# STM32H573xx register map
File version: 1.0
Registers are 32-bit, read-write, reset 0x0 unless marked. A register's access mark holds for its fields unless they carry their own. Offsets are from the block's base; [hi:lo] are bit positions; {n}, {i} and the like mark numbered series; 'fields as' and 'values as' point back to an identical list.

## ICACHE — Instruction Cache
Base 0x40030400
Same registers: ICACHE_S 0x50030400
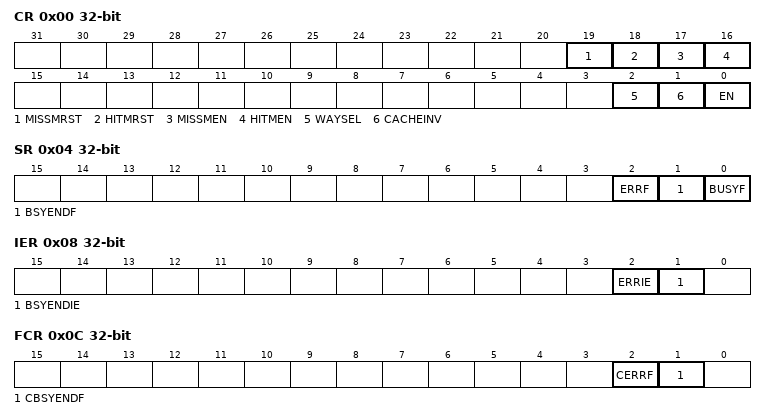
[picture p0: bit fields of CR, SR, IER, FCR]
0x00 CR — ICACHE control register
  [19] MISSMRST — Miss monitor reset
  [18] HITMRST — Hit monitor reset
  [17] MISSMEN — Miss monitor enable
  [16] HITMEN — Hit monitor enable
  [2] WAYSEL — Ways selection
    0=ICACHE_1WAY (1-way cache (direct mapped cache)); 1=ICACHE_2WAYS (2-ways set associative cache (default))
  [1] CACHEINV — Cache invalidation
  [0] EN — Enable
0x04 SR — ICACHE status register
  [2] ERRF — Cache error flag
  [1] BSYENDF — Busy end flag
  [0] BUSYF — Busy flag
0x08 IER — ICACHE interrupt enable register
  [2] ERRIE — Cache error interrupt enable
  [1] BSYENDIE — Busy end interrupt enable
0x0C FCR — ICACHE Flag clear register
  [2] CERRF — Cache error flag clear
  [1] CBSYENDF — Busy end flag clear
0x10 HMONR — ICACHE hit monitor register
  [31:0] HITMON — Cache hit monitor register
0x14 MMONR — ICACHE miss monitor register
  [15:0] MISSMON — Cache miss monitor register
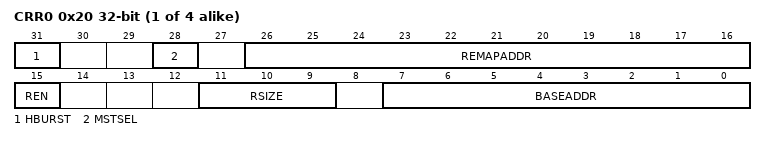
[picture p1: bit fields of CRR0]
{0x20+4i} CRR{i} (i=0..3) — ICACHE region {i} configuration register
  [31] HBURST — Region X output burst type
  [28] MSTSEL — Region X AHB cache master selection
  [26:16] REMAPADDR — Remap address of Region X to be remapped
  [15] REN — Region X enable
  [11:9] RSIZE — Region X size
  [7:0] BASEADDR — Base address of region X to remap

## DCACHE1 — Data Cache
Base 0x40031400
Same registers: DCACHE1_S 0x50031400
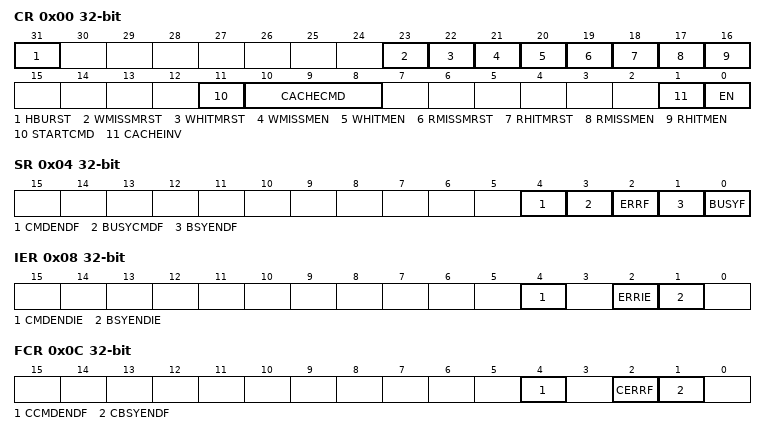
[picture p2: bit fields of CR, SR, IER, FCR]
0x00 CR — DCACHE control register
  [31] HBURST — Read burst type
    0=WRAP; 1=INCR
  [23] WMISSMRST — Write Miss monitor reset
  [22] WHITMRST — Write Hit monitor reset
  [21] WMISSMEN — Write Miss monitor enable
  [20] WHITMEN — Write Hit monitor enable
  [19] RMISSMRST — Read Miss monitor reset
  [18] RHITMRST — Read Hit monitor reset
  [17] RMISSMEN — Read Miss monitor enable
  [16] RHITMEN — Read Hit monitor enable
  [11] STARTCMD — Start command
  [10:8] CACHECMD — Cache command
    2=INVALIDATE_BY_ADDR; 1=CLEAN_BY_ADDR; 3=CLEAN_INVALIDATE_BY_ADDR; 0=NO_OPERATION
  [1] CACHEINV — Cache invalidation
  [0] EN — Enable
0x04 SR — DCACHE status register
  [4] CMDENDF — Command end flag
  [3] BUSYCMDF — Busy command flag
  [2] ERRF — Cache error flag
  [1] BSYENDF — Busy end flag
  [0] BUSYF — Busy flag
0x08 IER — DCACHE interrupt enable register
  [4] CMDENDIE — Command end interrupt enable
  [2] ERRIE — Cache error interrupt enable
  [1] BSYENDIE — Busy end interrupt enable
0x0C FCR — DCACHE Flag clear register
  [4] CCMDENDF — Command end flag clear
  [2] CERRF — Cache error flag clear
  [1] CBSYENDF — Busy end flag clear
0x10 RHMONR — DCACHE Read hit monitor register
  [31:0] RHITMON — Cache Read hit monitor register
0x14 RMMONR — DCACHE Read miss monitor register
  [15:0] RMISSMON — Cache Read miss monitor register
0x20 WHMONR — DCACHE Write hit monitor register
  [31:0] WHITMON — Cache Read hit monitor register
0x24 WMMONR — DCACHE Write miss monitor register
  [15:0] WMISSMON — Cache Read miss monitor register
0x28 CMDRSADDRR — DCACHE Command Start Address register
  [31:4] CMDSTARTADDR — Command start address
0x2C CMDREADDRR — DCACHE Command End Address register
  [31:4] CMDENDADDR — Command end address

## GTZC_TZSC1 — Global TrustZone Controller
Base 0x40032400
Same registers: GTZC_TZSC1_S 0x50032400
0x00 CR — TZSC control register
  [0] LCK
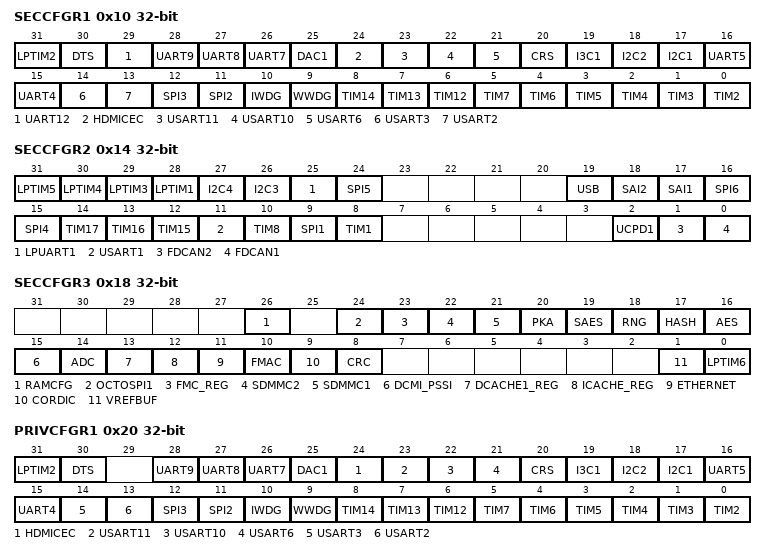
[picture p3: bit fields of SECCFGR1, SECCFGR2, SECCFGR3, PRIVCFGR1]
0x10 SECCFGR1 — TZSC secure configuration register 1
  [31] LPTIM2, [30] DTS, [29] UART12, [28] UART9, [27] UART8, [26] UART7, [25] DAC1, [24] HDMICEC, [23] USART11, [22] USART10, [21] USART6, [20] CRS, [19] I3C1, [18] I2C2, [17] I2C1, [16] UART5, [15] UART4, [14] USART3, [13] USART2, [12] SPI3, [11] SPI2, [10] IWDG, [9] WWDG, [8] TIM14, [7] TIM13, [6] TIM12, [n-2] TIM{n} (n=2..7)
0x14 SECCFGR2 — TZSC secure configuration register 2
  [31] LPTIM5, [30] LPTIM4, [29] LPTIM3, [28] LPTIM1, [27] I2C4, [26] I2C3, [25] LPUART1, [24] SPI5, [19] USB, [18] SAI2, [17] SAI1, [16] SPI6, [15] SPI4, [14] TIM17, [13] TIM16, [12] TIM15, [11] USART1, [10] TIM8, [9] SPI1, [8] TIM1, [2] UCPD1, [1] FDCAN2, [0] FDCAN1
0x18 SECCFGR3 — TZSC secure configuration register 3
  [26] RAMCFG, [24] OCTOSPI1, [23] FMC_REG, [22] SDMMC2, [21] SDMMC1, [20] PKA, [19] SAES, [18] RNG, [17] HASH, [16] AES, [15] DCMI_PSSI, [14] ADC, [13] DCACHE1_REG, [12] ICACHE_REG, [11] ETHERNET, [10] FMAC, [9] CORDIC, [8] CRC, [1] VREFBUF, [0] LPTIM6
0x20 PRIVCFGR1 — TZSC privilege configuration register 1
  [31] LPTIM2, [30] DTS, [28] UART9, [27] UART8, [26] UART7, [25] DAC1, [24] HDMICEC, [23] USART11, [22] USART10, [21] USART6, [20] CRS, [19] I3C1, [18] I2C2, [17] I2C1, [16] UART5, [15] UART4, [14] USART3, [13] USART2, [12] SPI3, [11] SPI2, [10] IWDG, [9] WWDG, [8] TIM14, [7] TIM13, [6] TIM12, [n-2] TIM{n} (n=2..7)
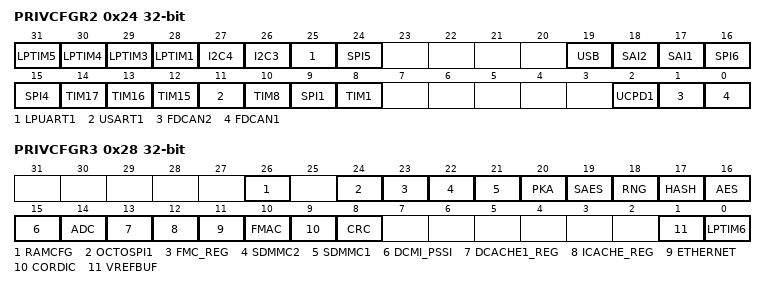
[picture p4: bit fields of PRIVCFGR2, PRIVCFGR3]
0x24 PRIVCFGR2 — TZSC privilege configuration register 2
  fields as SECCFGR2
0x28 PRIVCFGR3 — TZSC privilege configuration register 3
  fields as SECCFGR3
{0x30+0x10*i} MPCWM{i}ACFGR (i=1..4) — TZSC memory {i} sub-region A watermark configuration register
{0x34+0x10*i} MPCWM{i}AR (i=1..4) — TZSC memory {i} sub-region A watermark register
{0x38+0x10*i} MPCWM{i}BCFGR (i=1..4) — TZSC memory {i} sub-region B watermark configuration register
{0x3C+0x10*i} MPCWM{i}BR (i=1..4) — TZSC memory {i} sub-region B watermark register
